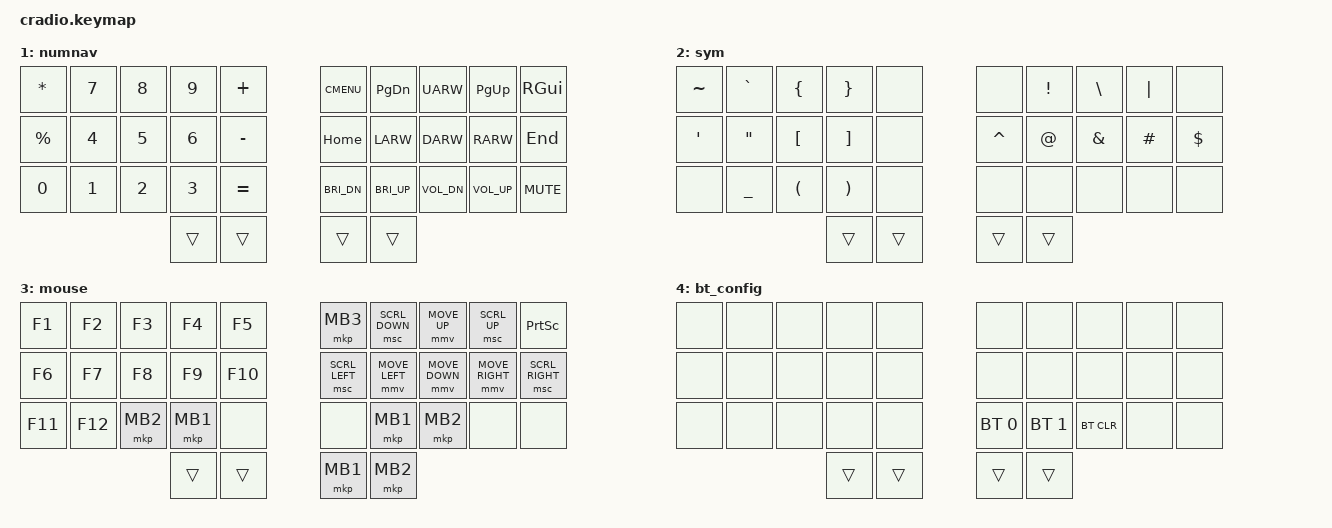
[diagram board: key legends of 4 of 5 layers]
// Copyright (c) 2022 The ZMK Contributors
// SPDX-License-Identifier: MIT

#include <behaviors.dtsi>
#include <dt-bindings/zmk/keys.h>
#include <dt-bindings/zmk/bt.h>
#include <dt-bindings/zmk/pointing.h>

// Home row mods macro
#define HRML(k1,k2,k3) &ht LSHFT k1  &ht LCTRL k2  &ht LALT k3
#define HRMR(k1,k2,k3) &ht LALT k1 &ht RCTRL k2  &ht LSHFT k3 
#define ZMK_POINTING_DEFAULT_MOVE_VAL 600
#define ZMK_POINTING_DEFAULT_SCRL_VAL 10

/ {

    behaviors {
        ht: hold_tap {
            label = "hold_tap";
            compatible = "zmk,behavior-hold-tap";
            #binding-cells = <2>;
            flavor = "tap-preferred";
            tapping-term-ms = <220>;
            quick-tap-ms = <150>;
            global-quick-tap;
            bindings = <&kp>, <&kp>;
        };
    };

    combos {
        compatible = "zmk,combos";
        combo_qw_esc {
            timeout-ms = <50>;
            key-positions = <0 1>;
            bindings = <&kp ESC>;
        };
        combo_op_canc {
            timeout-ms = <50>;
            key-positions = <8 9>;
            bindings = <&kp DEL>;
        };
    };

    keymap {
        compatible = "zmk,keymap";

        default_layer {
            bindings = <
// ╭──────────┬──────────┬──────────┬──────────┬──────────╮ ╭──────────┬──────────┬──────────┬──────────┬──────────╮
// │    Q     │    W     │    E     │    R     │    T     │ │    Y     │    U     │    I     │    O     │    P     │
      &lt 4 Q      &kp W      &kp E      &kp R      &kp T        &kp Y      &kp U      &kp I      &kp O      &kp P
// ├──────────┼──────────┼──────────┼──────────┼──────────┤ ├──────────┼──────────┼──────────┼──────────┼──────────┤
// │    A     │  GUI/S   │  ALT/D   │  CTL/F   │  SFT/G   │ │  SFT/H   │  CTL/J   │  ALT/K   │  GUI/L   │    ;     │
      HRML(A,        S,         D)      &kp F      &kp G        &kp H   &kp J     HRMR(K,         L,      SEMI)
// ├──────────┼──────────┼──────────┼──────────┼──────────┤ ├──────────┼──────────┼──────────┼──────────┼──────────┤
// │ LT2/Z    │    X     │    C     │    V     │    B     │ │    N     │    M     │    ,     │    .     │ LT2/ /   │
      &lt 2 Z    &kp X      &kp C      &kp V      &kp B        &kp N      &kp M      &kp COMMA  &kp DOT    &lt 2 FSLH
// ╰──────────┴──────────┴──────────┼──────────┼──────────┤ ├──────────┼──────────┼──────────┴──────────┴──────────╯
//                                  │ LT3/TAB  │ LT1/SPC  │ │ LT1/BSPC │ LT3/ENT  │
                                     &lt 3 TAB   &lt 1 SPACE   &lt 1 BSPC   &lt 3 ENTER
//                                  ╰──────────┴──────────╯ ╰──────────┴──────────╯
            >;
        };

        numnav {
            bindings = <
// ╭──────────┬──────────┬──────────┬──────────┬──────────╮ ╭──────────┬──────────┬──────────┬──────────┬──────────╮
// │     *    |   7      │   8      │    9     |    +     │ | MENU   │  PG_DN   │  UP      |  PG_UP   │   GUI │
      &kp STAR  &kp N7     &kp N8     &kp N9   &kp PLUS     &kp K_CMENU    &kp PG_DN &kp UARW  &kp PG_UP   &kp RGUI
// ├──────────┼──────────┼──────────┼──────────┼──────────┤ ├──────────┼──────────┼──────────┼──────────┼──────────┤
// │   %      |   4      │    5     |     6    │    -     │ │  HOME     LEFT   │   DOWN   │  │  RIGHT   │ END    
     &kp PRCNT   &kp N4    &kp N5      &kp N6   &kp MINUS     &kp HOME &kp LARW   &kp DARW      &kp RARW  &kp END
// ├──────────┼──────────┼──────────┼──────────┼──────────┤ ├──────────┼──────────┼──────────┼──────────┼──────────┤
//     0    │  1     │    2     │    3    │  │    =     │   │  BRI_DN  │  BRI_UP  │   MUTE   │  VOL_DN  │  VOL_UP  │
    &kp N0   &kp N1     &kp N2     &kp N3       &kp EQUAL      &kp C_BRI_DN &kp C_BRI_UP &kp C_VOL_DN &kp C_VOL_UP &kp C_MUTE
// ╰──────────┴──────────┴──────────┼──────────┼──────────┤ ├──────────┼──────────┼──────────┴──────────┴──────────╯
                                       &trans     &trans       &trans     &trans
            >;
        };

        sym {
            bindings = <
// ╭──────────┬──────────┬──────────┬──────────┬──────────╮ ╭──────────┬──────────┬──────────┬──────────┬──────────╮
// │    ~     │    `     │    {     │    }     │  NONE    │    NONE    |    !     |    \     │    |     │    NONE  │
     &kp TILDE  &kp GRAVE   &kp LBRC   &kp RBRC    &none        &none     &kp EXCL    &kp BSLH   &kp PIPE    &none    
// ├──────────┼──────────┼──────────┼──────────┼──────────┤ ├──────────┼──────────┼──────────┼──────────┼──────────┤
// │    '     │    "     │    [     │    ]     │  NONE   │ │    ^     │      @     |   &     #     │     |    $   │   
      &kp SQT    &kp DQT      &kp LBKT   &kp RBKT  &none      &kp CARET   &kp AT &kp AMPS    &kp HASH   &kp DOLLAR
// ├──────────┼──────────┼──────────┼──────────┼──────────┤ ├──────────┼──────────┼──────────┼──────────┼──────────┤
// │   NONE   │    _     │    (     │    )     │  NONE    │ |   NONE   | |   NONE   │  NONE  NONE   │   NONE   │   
      &none      &kp UNDER    &kp LPAR   &kp RPAR &none      &none          &none      &none &none      &none
// ╰──────────┴──────────┴──────────┼──────────┼──────────┤ ├──────────┼──────────┼──────────┴──────────┴──────────╯
                                       &trans     &trans       &trans     &trans
            >;
        };

        mouse {
            bindings = <
// ╭──────────┬──────────┬──────────┬──────────┬──────────╮ ╭──────────┬──────────┬──────────┬──────────┬──────────╮
       &kp F1   &kp F2    &kp F3    &kp F4    &kp F5      &mkp MB3 &msc SCRL_DOWN &mmv MOVE_UP &msc SCRL_UP  &kp PSCRN
// ├──────────┼──────────┼──────────┼──────────┼──────────┤ ├──────────┼──────────┼──────────┼──────────┼──────────┤
       &kp F6     &kp F7     &kp F8 &kp F9 &kp F10        &msc SCRL_LEFT &mmv MOVE_LEFT  &mmv MOVE_DOWN &mmv MOVE_RIGHT &msc SCRL_RIGHT
// ├──────────┼──────────┼──────────┼──────────┼──────────┤ ├──────────┼──────────┼──────────┼──────────┼──────────┤
       &kp F11     &kp F12     &mkp MB2 &mkp MB1    &none    &none        &mkp MB1   &mkp MB2   &none      &none
// ╰──────────┴──────────┴──────────┼──────────┼──────────┤ ├──────────┼──────────┼──────────┴──────────┴──────────╯
                                       &trans     &trans       &mkp MB1   &mkp MB2
            >;
        };
        bt_config {
            bindings = <
                &none &none &none &none &none          &none &none &none &none &none 
                &none &none &none &none &none          &none &none &none &none &none 
                &none &none &none &none &none          &bt BT_SEL 0 &bt BT_SEL 1 &bt BT_CLR &none &none 
                    &trans     &trans                   &trans   &trans
            >;
    };
};
};
